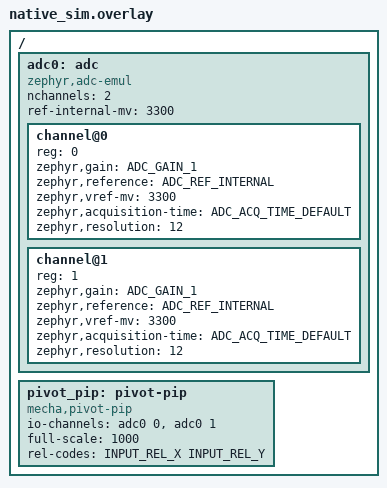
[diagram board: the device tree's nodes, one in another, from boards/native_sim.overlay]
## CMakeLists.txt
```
# Copyright (c) 2026 Mecha Systems
# SPDX-License-Identifier: BSD-3-Clause

cmake_minimum_required(VERSION 3.20.0)

find_package(Zephyr REQUIRED HINTS $ENV{ZEPHYR_BASE})
project(pivot_pip_sample)

target_sources(app PRIVATE src/main.c)
```

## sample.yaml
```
# Copyright (c) 2026 Mecha Systems
# SPDX-License-Identifier: BSD-3-Clause

sample:
  name: Mecha Pivot Pip
  description: Report the motion of a simulated Pivot Pip through the input subsystem.

tests:
  sample.mecha.pivot_pip:
    tags: mecha_pivot_pip
    platform_allow:
      - native_sim
      - native_sim/native/64
    integration_platforms:
      - native_sim/native/64
    harness: console
    harness_config:
      type: multi_line
      ordered: true
      regex:
        - "Pivot Pip sample: pushing the stick to the right"
        - "pointer moved x by"
        - "Pivot Pip sample: done"
```

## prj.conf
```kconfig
CONFIG_INPUT=y
CONFIG_ADC=y
CONFIG_ADC_EMUL=y
```

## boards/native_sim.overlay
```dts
/*
 * Copyright (c) 2026 Mecha Systems
 *
 * SPDX-License-Identifier: BSD-3-Clause
 */

#include <zephyr/dt-bindings/adc/adc.h>
#include <zephyr/dt-bindings/input/input-event-codes.h>

/*
 * An emulated ADC stands in for the real one. On a board, point io-channels at the
 * ADC channels that the stick is wired to, for example the channels of an ADS1115.
 */
/ {
	adc0: adc {
		compatible = "zephyr,adc-emul";
		nchannels = <2>;
		ref-internal-mv = <3300>;
		#io-channel-cells = <1>;
		#address-cells = <1>;
		#size-cells = <0>;
		status = "okay";

		channel@0 {
			reg = <0>;
			zephyr,gain = "ADC_GAIN_1";
			zephyr,reference = "ADC_REF_INTERNAL";
			zephyr,vref-mv = <3300>;
			zephyr,acquisition-time = <ADC_ACQ_TIME_DEFAULT>;
			zephyr,resolution = <12>;
		};

		channel@1 {
			reg = <1>;
			zephyr,gain = "ADC_GAIN_1";
			zephyr,reference = "ADC_REF_INTERNAL";
			zephyr,vref-mv = <3300>;
			zephyr,acquisition-time = <ADC_ACQ_TIME_DEFAULT>;
			zephyr,resolution = <12>;
		};
	};

	pivot_pip: pivot-pip {
		compatible = "mecha,pivot-pip";
		io-channels = <&adc0 0>, <&adc0 1>;
		io-channel-names = "x", "y";
		full-scale = <1000>;
		rel-codes = <INPUT_REL_X INPUT_REL_Y>;
	};
};
```

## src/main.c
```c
/*
 * Copyright (c) 2026 Mecha Systems
 *
 * SPDX-License-Identifier: BSD-3-Clause
 */

/*
 * Push a simulated Pivot Pip to the right and print the motion that the driver reports.
 * A real application reads the same events from the input subsystem, for example through
 * a zmk,input-listener in ZMK.
 */

#include <zephyr/device.h>
#include <zephyr/drivers/adc/adc_emul.h>
#include <zephyr/init.h>
#include <zephyr/input/input.h>
#include <zephyr/kernel.h>
#include <zephyr/sys/printk.h>

#define PIVOT_PIP DEVICE_DT_GET(DT_NODELABEL(pivot_pip))
#define ADC       DEVICE_DT_GET(DT_NODELABEL(adc0))

#define REST 2048
#define PUSH 1000

static void on_input(struct input_event *evt, void *user_data)
{
	ARG_UNUSED(user_data);

	if (evt->type == INPUT_EV_REL) {
		printk("pointer moved %s by %d\n", evt->code == INPUT_REL_X ? "x" : "y",
		       evt->value);
	}
}
INPUT_CALLBACK_DEFINE(PIVOT_PIP, on_input, NULL);

/* The driver measures the idle centre as soon as it starts, so the emulated stick starts at rest.
 */
static int stick_at_rest(void)
{
	adc_emul_const_raw_value_set(ADC, 0, REST);
	adc_emul_const_raw_value_set(ADC, 1, REST);

	return 0;
}
SYS_INIT(stick_at_rest, POST_KERNEL, 60);

int main(void)
{
	printk("Pivot Pip sample: stick at rest\n");
	k_msleep(500);

	printk("Pivot Pip sample: pushing the stick to the right\n");
	adc_emul_const_raw_value_set(ADC, 0, REST + PUSH);
	k_msleep(500);

	printk("Pivot Pip sample: releasing the stick\n");
	adc_emul_const_raw_value_set(ADC, 0, REST);
	k_msleep(500);

	printk("Pivot Pip sample: done\n");

	return 0;
}
```
